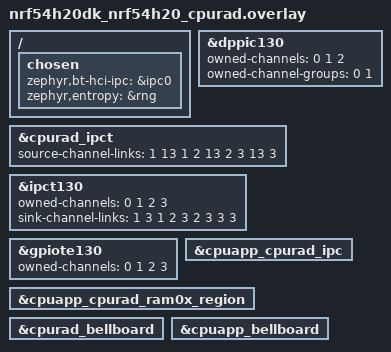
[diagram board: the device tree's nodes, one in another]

// #include <common/nordic_nrf_next/nrfx_ram3x_dma.dtsi>

// / {
// 	chosen {
// 		zephyr,console = &uart135;
// 	};
// };

// /* ram3x_cpurad buffer is used by Radio core UART driver. */
// &ram3x_cpurad {
// 	status = "okay";
// };

// /* Configure Radio core UART. */
// &uart135 {
// 	status = "okay";
// 	memory-regions = <&ram3x_cpurad>;
// };

/ {
	chosen {
		//zephyr,console = &uart135;
		zephyr,bt-hci-ipc = &ipc0;
		zephyr,entropy = &rng;
	};
};

// /* ram3x_cpurad buffer is used by Radio core UART driver. */
// &ram3x_cpurad {
// 	status = "okay";
// };

// /* Configure Radio core UART. */
// &uart135 {
// 	status = "okay";
// 	memory-regions = <&ram3x_cpurad>;
// };

/ {
	// gpio_toggle_pin_0: gpio-toggle-pin-0 {
	// 	compatible = "nordic,gpio-pins";
	// 	gpios = <&gpio0 0 GPIO_ACTIVE_HIGH>;
	// 	status = "okay";
	// };

	// gpio_toggle_pin_1: gpio-toggle-pin-1 {
	// 	compatible = "nordic,gpio-pins";
	// 	gpios = <&gpio0 1 GPIO_ACTIVE_HIGH>;
	// 	status = "okay";
	// };

	// gpio_toggle_pin_2: gpio-toggle-pin-2 {
	// 	compatible = "nordic,gpio-pins";
	// 	gpios = <&gpio0 2 GPIO_ACTIVE_HIGH>;
	// 	status = "okay";
	// };

	// gpio_toggle_pin_3: gpio-toggle-pin-3 {
	// 	compatible = "nordic,gpio-pins";
	// 	gpios = <&gpio0 3 GPIO_ACTIVE_HIGH>;
	// 	status = "okay";
	// };

	// gpio_toggle_pin_4: gpio-toggle-pin-4 {
	// 	compatible = "nordic,gpio-pins";
	// 	gpios = <&gpio0 4 GPIO_ACTIVE_HIGH>;
	// 	status = "okay";
	// };

	// gpio_toggle_pin_5: gpio-toggle-pin-5 {
	// 	compatible = "nordic,gpio-pins";
	// 	gpios = <&gpio0 5 GPIO_ACTIVE_HIGH>;
	// 	status = "okay";
	// };

	// gpio_toggle_pin_6: gpio-toggle-pin-6 {
	// 	compatible = "nordic,gpio-pins";
	// 	gpios = <&gpio0 6 GPIO_ACTIVE_HIGH>;
	// 	status = "okay";
	// };

	// gpio_toggle_pin_7: gpio-toggle-pin-7 {
	// 	compatible = "nordic,gpio-pins";
	// 	gpios = <&gpio0 7 GPIO_ACTIVE_HIGH>;
	// 	status = "okay";
	// };

	/*gpio_toggle_pin_8: gpio-toggle-pin-8 {
		compatible = "nordic,gpio-pins";
		gpios = <&gpio1 0 GPIO_ACTIVE_HIGH>;
		status = "okay";
	};

	gpio_toggle_pin_9: gpio-toggle-pin-9 {
		compatible = "nordic,gpio-pins";
		gpios = <&gpio1 1 GPIO_ACTIVE_HIGH>;
		status = "okay";
	};

	gpio_toggle_pin_10: gpio-toggle-pin-10 {
		compatible = "nordic,gpio-pins";
		gpios = <&gpio1 2 GPIO_ACTIVE_HIGH>;
		status = "okay";
	};

	gpio_toggle_pin_11: gpio-toggle-pin-11 {
		compatible = "nordic,gpio-pins";
		gpios = <&gpio1 3 GPIO_ACTIVE_HIGH>;
		status = "okay";
	};

	gpio_toggle_pin_12: gpio-toggle-pin-12 {
		compatible = "nordic,gpio-pins";
		gpios = <&gpio1 4 GPIO_ACTIVE_HIGH>;
		status = "okay";
	};

	gpio_toggle_pin_13: gpio-toggle-pin-13 {
		compatible = "nordic,gpio-pins";
		gpios = <&gpio1 5 GPIO_ACTIVE_HIGH>;
		status = "okay";
	};

	gpio_toggle_pin_14: gpio-toggle-pin-14 {
		compatible = "nordic,gpio-pins";
		gpios = <&gpio1 6 GPIO_ACTIVE_HIGH>;
		status = "okay";
	};

	gpio_toggle_pin_15: gpio-toggle-pin-15 {
		compatible = "nordic,gpio-pins";
		gpios = <&gpio1 8 GPIO_ACTIVE_HIGH>;
		status = "okay";
	};*/
};

&dppic130 {
	owned-channels = <0 1 2>;
	owned-channel-groups = <0 1>;
	status = "okay";
};

&cpurad_ipct {
	source-channel-links = <1 13 1
				2 13 2
				3 13 3>;
};

&ipct130 {
	status = "okay";
	owned-channels = <0 1 2 3>;
	sink-channel-links = <1 3 1
			      2 3 2
			      3 3 3>;
};

&gpiote130 {
	status = "okay";
	owned-channels = <0 1 2 3>;
};

/* IPC for "remote" from APP core perspective */
ipc0: &cpuapp_cpurad_ipc {
	status = "okay";
};

&cpuapp_cpurad_ram0x_region {
	status = "okay";
};

&cpurad_bellboard {
	status = "okay";
};

&cpuapp_bellboard {
	status = "okay";
};
